VERSION ""

NS_ :

BS_:

BU_: XXX

BO_ 528 TRACK_0: 8 XXX
 SG_ LONG_DIST : 15|16@0- (1,0) [0|65535] "" XXX
 SG_ COUNTER : 7|8@0+ (1,0) [0|255] "" XXX

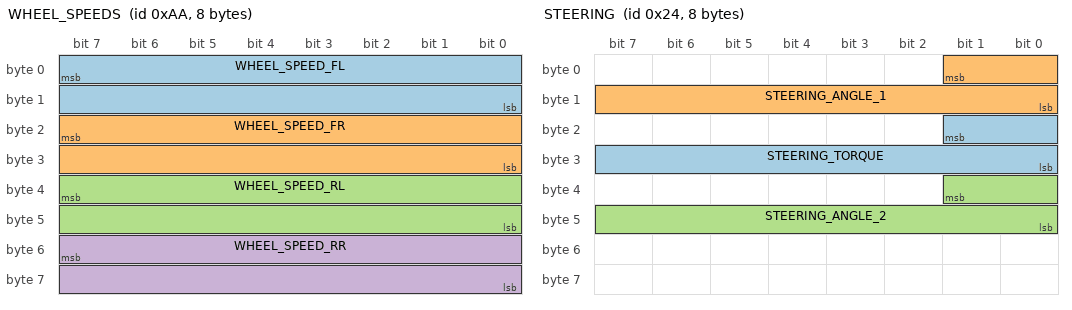
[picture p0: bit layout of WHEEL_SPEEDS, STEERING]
BO_ 170 WHEEL_SPEEDS: 8 XXX
 SG_ WHEEL_SPEED_FL : 7|16@0+ (1,-6767) [0|65535] "" XXX
 SG_ WHEEL_SPEED_FR : 23|16@0+ (1,-6767) [0|65535] "" XXX
 SG_ WHEEL_SPEED_RL : 39|16@0+ (1,-6767) [0|65535] "" XXX
 SG_ WHEEL_SPEED_RR : 55|16@0+ (1,-6767) [0|65535] "" XXX

BO_ 552 ACCELEROMETER: 8 XXX
 SG_ ACCEL_Z : 22|15@0- (1,0) [0|32767] "" XXX
 SG_ ACCEL_X : 6|15@0- (1,0) [0|32767] "" XXX

BO_ 166 BRAKE: 8 XXX
 SG_ BRAKE_AMOUNT : 7|8@0+ (1,0) [0|255] "" XXX
 SG_ BRAKE_PEDAL : 23|8@0+ (1,0) [0|255] "" XXX

BO_ 36 STEERING: 8 XXX
 SG_ STEERING_TORQUE : 17|10@0+ (1,-512) [0|65535] "" XXX
 SG_ STEERING_ANGLE_1 : 1|10@0+ (1,-512) [0|65535] "" XXX
 SG_ STEERING_ANGLE_2 : 33|10@0+ (1,-512) [0|65535] "" XXX

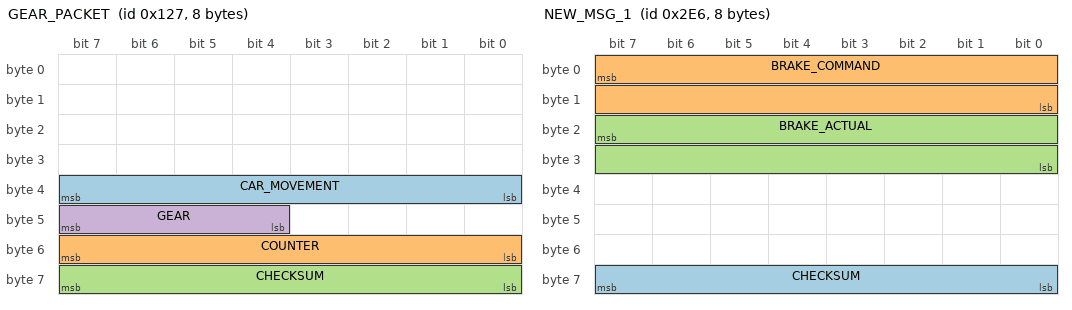
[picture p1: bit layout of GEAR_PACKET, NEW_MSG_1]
BO_ 295 GEAR_PACKET: 8 XXX
 SG_ CAR_MOVEMENT : 39|8@0- (1,0) [0|255] "" XXX
 SG_ COUNTER : 55|8@0+ (1,0) [0|255] "" XXX
 SG_ CHECKSUM : 63|8@0+ (1,0) [0|255] "" XXX
 SG_ GEAR : 47|4@0+ (1,0) [0|15] "" XXX

BO_ 608 NEW_MSG_2: 8 XXX
 SG_ NEW_SIGNAL_1 : 15|16@0- (1,0) [0|65535] "" XXX

BO_ 742 NEW_MSG_1: 8 XXX
 SG_ CHECKSUM : 63|8@0+ (1,0) [0|255] "" XXX
 SG_ BRAKE_COMMAND : 7|16@0- (1,0) [0|65535] "" XXX
 SG_ BRAKE_ACTUAL : 23|16@0- (1,0) [0|65535] "" XXX

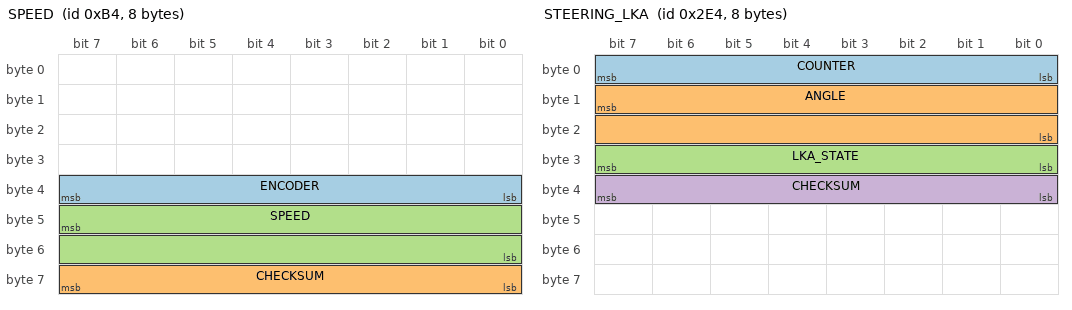
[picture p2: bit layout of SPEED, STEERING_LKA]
BO_ 180 SPEED: 8 XXX
 SG_ ENCODER : 39|8@0+ (1,0) [0|255] "" XXX
 SG_ CHECKSUM : 63|8@0+ (1,0) [0|255] "" XXX
 SG_ SPEED : 47|16@0+ (1,0) [0|65535] "" XXX

BO_ 643 PRE_COLLISION: 8 XXX

BO_ 614 STEERING_IPAS: 8 XXX
 SG_ FLAG : 7|4@0+ (1,0) [0|15] "" XXX
 SG_ ANGLE : 3|12@0- (1,0) [0|16777215] "" XXX

BO_ 740 STEERING_LKA: 8 XXX
 SG_ COUNTER : 7|8@0+ (1,0) [0|255] "" XXX
 SG_ ANGLE : 15|16@0- (1,0) [0|65535] "" XXX
 SG_ LKA_STATE : 31|8@0+ (1,0) [0|255] "" XXX
 SG_ CHECKSUM : 39|8@0+ (1,0) [0|255] "" XXX
